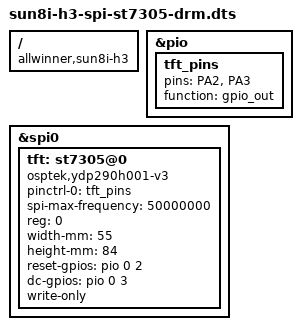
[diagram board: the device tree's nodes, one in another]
/dts-v1/;
/plugin/;

/ {
	compatible = "allwinner,sun8i-h3";

	fragment@0 {
		target = <&pio>;
		__overlay__ {
			tft_pins: tft_pins {
				pins = "PA2", "PA3";
				function = "gpio_out";
			};
		};
	};

	fragment@1 {
		target = <&spi0>;
		__overlay__ {
			status = "okay";

			tft: st7305@0 {
				#address-cells = <1>;
				#size-cells = <1>;

				pinctrl-names = "default";
				pinctrl-0 = <&tft_pins>;

				compatible = "osptek,ydp290h001-v3";

				spi-max-frequency = <50000000>;
				reg = <0>;

				width-mm = <55>;
				height-mm = <84>;

				reset-gpios = <&pio 0 2 0>;
				dc-gpios = <&pio 0 3 0>;
				write-only;

				status = "okay";
			};
		};
	};
};

